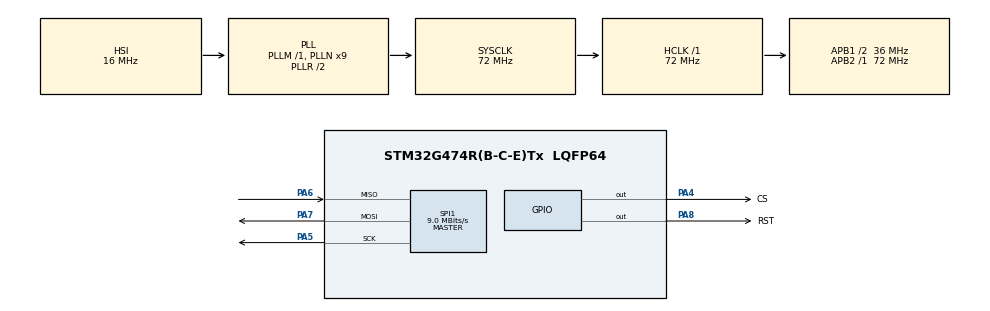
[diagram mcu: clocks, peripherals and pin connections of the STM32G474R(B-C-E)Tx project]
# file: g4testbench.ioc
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Mcu.Family=STM32G4
Mcu.Name=STM32G474R(B-C-E)Tx
Mcu.Package=LQFP64
NVIC.PriorityGroup=NVIC_PRIORITYGROUP_4
PA4.GPIO_Label=CS
PA4.Signal=GPIO_Output
PA5.Mode=Full_Duplex_Master
PA5.Signal=SPI1_SCK
PA6.Mode=Full_Duplex_Master
PA6.Signal=SPI1_MISO
PA7.Mode=Full_Duplex_Master
PA7.Signal=SPI1_MOSI
PA8.GPIO_Label=RST
PA8.Signal=GPIO_Output
ProjectManager.HeapSize=0x200
ProjectManager.StackSize=0x400
ProjectManager.TargetToolchain=STM32CubeIDE
RCC.ADC12Freq_Value=72000000
RCC.ADC345Freq_Value=72000000
RCC.AHBFreq_Value=72000000
RCC.APB1CLKDivider=RCC_HCLK_DIV2
RCC.APB1Freq_Value=36000000
RCC.APB1TimFreq_Value=72000000
RCC.APB2Freq_Value=72000000
RCC.APB2TimFreq_Value=72000000
RCC.CK48CLockSelection=RCC_USBCLKSOURCE_HSI48
RCC.CortexFreq_Value=72000000
RCC.EXTERNAL_CLOCK_VALUE=12288000
RCC.HCLKFreq_Value=72000000
RCC.HSE_VALUE=8000000
RCC.HSI48_VALUE=48000000
RCC.HSI_VALUE=16000000
RCC.LSE_VALUE=32768
RCC.PLLN=9
RCC.PLLP=RCC_PLLP_DIV8
RCC.PLLQ=RCC_PLLQ_DIV8
RCC.SYSCLKFreq_VALUE=72000000
RCC.SYSCLKSource=RCC_SYSCLKSOURCE_PLLCLK
RCC.USBFreq_Value=48000000
RCC.VCOOutputFreq_Value=144000000
SPI1.BaudRatePrescaler=SPI_BAUDRATEPRESCALER_8
SPI1.CalculateBaudRate=9.0 MBits/s
SPI1.DataSize=SPI_DATASIZE_8BIT
SPI1.Direction=SPI_DIRECTION_2LINES
SPI1.Mode=SPI_MODE_MASTER
SPI1.VirtualType=VM_MASTER
VP_SYS_VS_DBSignals.Mode=DisableDeadBatterySignals
board=B-G474E-DPOW1

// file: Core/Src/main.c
/* USER CODE BEGIN Header */
/**
  ******************************************************************************
  * @file           : main.c
  * @brief          : Main program body
  ******************************************************************************
  * @attention
  *
  * Copyright (c) 2024 STMicroelectronics.
  * All rights reserved.
  *
  * This software is licensed under terms that can be found in the LICENSE file
  * in the root directory of this software component.
  * If no LICENSE file comes with this software, it is provided AS-IS.
  *
  ******************************************************************************
  */
/* USER CODE END Header */
#include "main.h"
#define MAX_BLOCKS 64  // Adjust this based on your card's capacity

/* USER CODE BEGIN Includes */
#include "rc522.h"
#include "string.h"
/* USER CODE END Includes */

SPI_HandleTypeDef hspi1;

/* USER CODE BEGIN PV */
uint8_t status;
uint8_t str[MAX_LEN]; // Max_LEN = 16
uint8_t sNum[MAX_LEN];
uint8_t Readdata;
// Global variables for debugging and data storage
volatile uint8_t g_currentBlock = 0;
volatile uint8_t g_readStatus = 0;
volatile uint8_t g_authStatus = 0;

void SystemClock_Config(void);
static void MX_GPIO_Init(void);
static void MX_SPI1_Init(void);

// Global array to store all read data
volatile uint8_t g_allBlockData[MAX_BLOCKS][16] = {0};
volatile uint8_t g_blockReadStatus[MAX_BLOCKS] = {0};  // 0: Not read, 1: Read successfully

// Function prototypes
static void MX_GPIO_Init(void);
static void MX_SPI1_Init(void);
void SystemClock_Config(void);

int main(void)
{
  HAL_Init();
  SystemClock_Config();
  MX_GPIO_Init();
  MX_SPI1_Init();

  // Initialize MFRC522
  MFRC522_Init();

  uint8_t size;

  while (1)
  {
    status = MFRC522_Request(PICC_REQIDL, str);
    if (status == MI_OK)
    {
      status = MFRC522_Anticoll(str);
      if (status == MI_OK)
      {
        memcpy(sNum, str, 20);
        size = MFRC522_SelectTag(sNum);

        if (size > 0)
        {
          // Reset the read status array
          memset((void*)g_blockReadStatus, 0, MAX_BLOCKS);

          // Try reading without authentication first
          for (g_currentBlock = 0; g_currentBlock < MAX_BLOCKS; g_currentBlock++)
          {
            g_readStatus = MFRC522_Read(g_currentBlock, (uint8_t*)g_allBlockData[g_currentBlock]);

            if (g_readStatus != MI_OK)
            {
              // If read fails, try to authenticate
              uint8_t key[6] = {0xFF, 0xFF, 0xFF, 0xFF, 0xFF, 0xFF}; // Default key
              g_authStatus = MFRC522_Auth(PICC_AUTHENT1A, g_currentBlock, key, sNum);

              if (g_authStatus == MI_OK)
              {
                g_readStatus = MFRC522_Read(g_currentBlock, (uint8_t*)g_allBlockData[g_currentBlock]);
              }
              else
              {
                // Authentication failed, move to next sector
                g_currentBlock = ((g_currentBlock / 4) + 1) * 4 - 1;
                continue;
              }
            }

            if (g_readStatus == MI_OK)
            {
              g_blockReadStatus[g_currentBlock] = 1;  // Mark as successfully read
            }
          }

          MFRC522_Halt();
        }
      }
    }

    HAL_Delay(1000);  // Wait for 1 second before next read attempt
  }
}

void SystemClock_Config(void)
{
  RCC_OscInitTypeDef RCC_OscInitStruct = {0};
  RCC_ClkInitTypeDef RCC_ClkInitStruct = {0};

  /** Configure the main internal regulator output voltage
  */
  HAL_PWREx_ControlVoltageScaling(PWR_REGULATOR_VOLTAGE_SCALE1);

  /** Initializes the RCC Oscillators according to the specified parameters
  * in the RCC_OscInitTypeDef structure.
  */
  RCC_OscInitStruct.OscillatorType = RCC_OSCILLATORTYPE_HSI;
  RCC_OscInitStruct.HSIState = RCC_HSI_ON;
  RCC_OscInitStruct.HSICalibrationValue = RCC_HSICALIBRATION_DEFAULT;
  RCC_OscInitStruct.PLL.PLLState = RCC_PLL_ON;
  RCC_OscInitStruct.PLL.PLLSource = RCC_PLLSOURCE_HSI;
  RCC_OscInitStruct.PLL.PLLM = RCC_PLLM_DIV1;
  RCC_OscInitStruct.PLL.PLLN = 9;
  RCC_OscInitStruct.PLL.PLLP = RCC_PLLP_DIV8;
  RCC_OscInitStruct.PLL.PLLQ = RCC_PLLQ_DIV8;
  RCC_OscInitStruct.PLL.PLLR = RCC_PLLR_DIV2;
  if (HAL_RCC_OscConfig(&RCC_OscInitStruct) != HAL_OK)
  {
    Error_Handler();
  }

  /** Initializes the CPU, AHB and APB buses clocks
  */
  RCC_ClkInitStruct.ClockType = RCC_CLOCKTYPE_HCLK|RCC_CLOCKTYPE_SYSCLK
                              |RCC_CLOCKTYPE_PCLK1|RCC_CLOCKTYPE_PCLK2;
  RCC_ClkInitStruct.SYSCLKSource = RCC_SYSCLKSOURCE_PLLCLK;
  RCC_ClkInitStruct.AHBCLKDivider = RCC_SYSCLK_DIV1;
  RCC_ClkInitStruct.APB1CLKDivider = RCC_HCLK_DIV2;
  RCC_ClkInitStruct.APB2CLKDivider = RCC_HCLK_DIV1;

  if (HAL_RCC_ClockConfig(&RCC_ClkInitStruct, FLASH_LATENCY_2) != HAL_OK)
  {
    Error_Handler();
  }
}

static void MX_SPI1_Init(void)
{

  /* SPI1 parameter configuration*/
  hspi1.Instance = SPI1;
  hspi1.Init.Mode = SPI_MODE_MASTER;
  hspi1.Init.Direction = SPI_DIRECTION_2LINES;
  hspi1.Init.DataSize = SPI_DATASIZE_8BIT;
  hspi1.Init.CLKPolarity = SPI_POLARITY_LOW;
  hspi1.Init.CLKPhase = SPI_PHASE_1EDGE;
  hspi1.Init.NSS = SPI_NSS_SOFT;
  hspi1.Init.BaudRatePrescaler = SPI_BAUDRATEPRESCALER_8;
  hspi1.Init.FirstBit = SPI_FIRSTBIT_MSB;
  hspi1.Init.TIMode = SPI_TIMODE_DISABLE;
  hspi1.Init.CRCCalculation = SPI_CRCCALCULATION_DISABLE;
  hspi1.Init.CRCPolynomial = 7;
  hspi1.Init.CRCLength = SPI_CRC_LENGTH_DATASIZE;
  hspi1.Init.NSSPMode = SPI_NSS_PULSE_ENABLE;
  if (HAL_SPI_Init(&hspi1) != HAL_OK)
  {
    Error_Handler();
  }

}

static void MX_GPIO_Init(void)
{
  GPIO_InitTypeDef GPIO_InitStruct = {0};

  /* GPIO Ports Clock Enable */
  __HAL_RCC_GPIOA_CLK_ENABLE();

  /*Configure GPIO pin Output Level */
  HAL_GPIO_WritePin(GPIOA, CS_Pin|RST_Pin, GPIO_PIN_RESET);

  /*Configure GPIO pins : CS_Pin RST_Pin */
  GPIO_InitStruct.Pin = CS_Pin|RST_Pin;
  GPIO_InitStruct.Mode = GPIO_MODE_OUTPUT_PP;
  GPIO_InitStruct.Pull = GPIO_NOPULL;
  GPIO_InitStruct.Speed = GPIO_SPEED_FREQ_LOW;
  HAL_GPIO_Init(GPIOA, &GPIO_InitStruct);

}

void Error_Handler(void)
{
  __disable_irq();
  while (1)
  {
  }
}
